# ATmega16M1 device description
Architecture: AVR8; Family: megaAVR
Registers are 8-bit, access not given, no defined reset value unless marked. A register's access mark holds for its fields unless they carry their own. Offsets are from the block's base; [hi:lo] are bit positions; {n}, {i} and the like mark numbered series.

## TC0 (TC8 module) — Timer/Counter, 8-bit
Instances: TC0 0x00
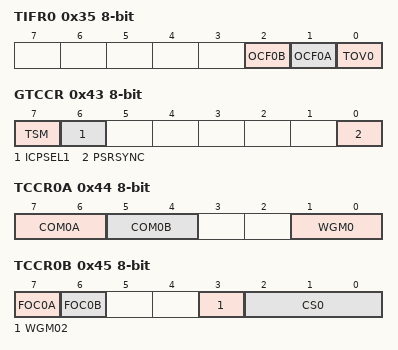
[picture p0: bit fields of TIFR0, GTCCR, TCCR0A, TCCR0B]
0x35 TIFR0 — Timer/Counter0 Interrupt Flag register
  [2] OCF0B — Timer/Counter0 Output Compare Flag 0B
  [1] OCF0A — Timer/Counter0 Output Compare Flag 0A
  [0] TOV0 — Timer/Counter0 Overflow Flag
0x43 GTCCR — General Timer/Counter Control Register
  [7] TSM — Timer/Counter Synchronization Mode
  [6] ICPSEL1 — Timer/Counter1 Input Capture Selection
  [0] PSRSYNC — Timer/Counter Prescaler Reset
0x44 TCCR0A — Timer/Counter Control Register A
  [7:6] COM0A — Compare Output Mode for Channel A
  [5:4] COM0B — Compare Output Mode for Channel B
  [1:0] WGM0 — Waveform Generation Mode
0x45 TCCR0B — Timer/Counter Control Register B
  [7] FOC0A — Force Output Compare A
  [6] FOC0B — Force Output Compare B
  [3] WGM02
  [2:0] CS0 — Clock Select
    0=No Clock Source (Stopped); 1=Running, No Prescaling; 2=Running, CLK/8; 3=Running, CLK/64; 4=Running, CLK/256; 5=Running, CLK/1024; 6=Running, ExtClk Tx Falling Edge; 7=Running, ExtClk Tx Rising Edge
0x46 TCNT0 — Timer/Counter0
  [7:0] TCNT0 — Timer/Counter0 bits
0x47 OCR0A — Timer/Counter0 Output Compare Register A
  [7:0] OCR0A — Timer/Counter0 Output Compare bits
0x48 OCR0B — Timer/Counter0 Output Compare Register B
  [7:0] OCR0B — Timer/Counter0 Output Compare bits
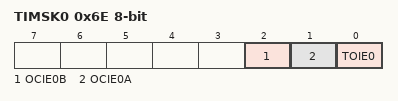
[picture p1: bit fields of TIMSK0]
0x6E TIMSK0 — Timer/Counter0 Interrupt Mask Register
  [2] OCIE0B — Timer/Counter0 Output Compare Match B Interrupt Enable
  [1] OCIE0A — Timer/Counter0 Output Compare Match A Interrupt Enable
  [0] TOIE0 — Timer/Counter0 Overflow Interrupt Enable

## TC1 (TC16 module) — Timer/Counter, 16-bit
Instances: TC1 0x00
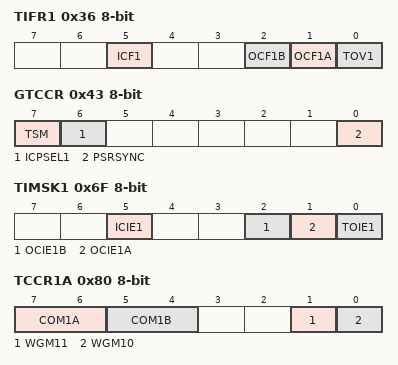
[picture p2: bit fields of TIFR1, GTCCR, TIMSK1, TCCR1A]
0x36 TIFR1 — Timer/Counter Interrupt Flag register
  [5] ICF1 — Input Capture Flag 1
  [2] OCF1B — Output Compare Flag 1B
  [1] OCF1A — Output Compare Flag 1A
  [0] TOV1 — Timer/Counter1 Overflow Flag
0x43 GTCCR — General Timer/Counter Control Register
  [7] TSM — Timer/Counter Synchronization Mode
  [6] ICPSEL1 — Timer/Counter1 Input Capture Selection
  [0] PSRSYNC — Timer/Counter Prescaler Reset
0x6F TIMSK1 — Timer/Counter Interrupt Mask Register
  [5] ICIE1 — Timer/Counter1 Input Capture Interrupt Enable
  [2] OCIE1B — Timer/Counter1 Output CompareB Match Interrupt Enable
  [1] OCIE1A — Timer/Counter1 Output CompareA Match Interrupt Enable
  [0] TOIE1 — Timer/Counter1 Overflow Interrupt Enable
0x80 TCCR1A — Timer/Counter1 Control Register A
  [7:6] COM1A — Compare Output Mode for Channel A
  [5:4] COM1B — Compare Output Mode for Channel B
  [1] WGM11 — Waveform Generation Mode
  [0] WGM10 — Waveform Generation Mode
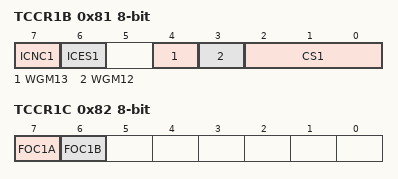
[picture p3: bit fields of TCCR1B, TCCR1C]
0x81 TCCR1B — Timer/Counter1 Control Register B
  [7] ICNC1 — Input Capture 1 Noise Canceler
  [6] ICES1 — Input Capture 1 Edge Select
  [4] WGM13 (bit 2 of the value upward) — Waveform Generation Mode
  [3] WGM12 (bit 2 of the value upward) — Waveform Generation Mode
  [2:0] CS1 — Prescaler source of Timer/Counter 1
    0=No Clock Source (Stopped); 1=Running, No Prescaling; 2=Running, CLK/8; 3=Running, CLK/64; 4=Running, CLK/256; 5=Running, CLK/1024; 6=Running, ExtClk Tx Falling Edge; 7=Running, ExtClk Tx Rising Edge
0x82 TCCR1C — Timer/Counter1 Control Register C
  [7] FOC1A — Force Output Compare for Channel A
  [6] FOC1B — Force Output Compare for Channel B
0x84 TCNT1 16-bit — Timer/Counter1 Bytes
  [15:0] TCNT1 — Timer/Counter1 bits
0x86 ICR1 16-bit — Timer/Counter1 Input Capture Register
  [15:0] ICR1 — Timer/Counter1 Input Capture bits
0x88 OCR1A 16-bit — Timer/Counter1 Output Compare Register A
  [15:0] OCR1A — Timer/Counter1 Output Compare bits
0x8A OCR1B 16-bit — Timer/Counter1 Output Compare Register B
  [15:0] OCR1B — Timer/Counter1 Output Compare bits

## ADC — Analog-to-Digital Converter
Instances: ADC 0x00
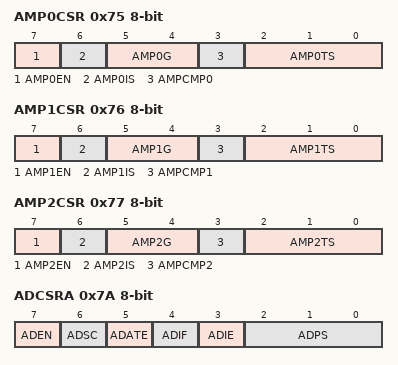
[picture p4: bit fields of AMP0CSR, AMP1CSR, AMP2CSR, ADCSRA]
0x75 AMP0CSR — Amplifier 0 Control and Status Register
  [7] AMP0EN — Amplifier 0 Enable
  [6] AMP0IS — Amplifier 0 Input Shunt
  [5:4] AMP0G — Amplifier 0 Gain Selection
  [3] AMPCMP0 — Amplifier 0 - Comparator 0 connection
  [2:0] AMP0TS — Amplifier 0 Clock Source Selection
0x76 AMP1CSR — Amplifier 1 Control and Status Register
  [7] AMP1EN — Amplifier 1 Enable
  [6] AMP1IS — Amplifier 1 Input Shunt
  [5:4] AMP1G — Amplifier 1 Gain Selection
  [3] AMPCMP1 — Amplifier 1 - Comparator 1 Connection
  [2:0] AMP1TS — Amplifier 1 Clock Source Selection
0x77 AMP2CSR — Amplifier 2 Control and Status Register
  [7] AMP2EN — Amplifier 2 Enable
  [6] AMP2IS — Amplifier 2 Input Shunt
  [5:4] AMP2G — Amplifier 2 Gain Selection
  [3] AMPCMP2 — Amplifier 2 - Comparator 2 Connection
  [2:0] AMP2TS — Amplifier 2 Clock Source Selection
0x78 ADC 16-bit — ADC Data Register Bytes
  [15:0] ADC — ADC Data bits
0x7A ADCSRA — The ADC Control and Status register
  [7] ADEN — ADC Enable
  [6] ADSC — ADC Start Conversion
  [5] ADATE — ADC Auto Trigger Enable
  [4] ADIF — ADC Interrupt Flag
  [3] ADIE — ADC Interrupt Enable
  [2:0] ADPS — ADC Prescaler Select Bits
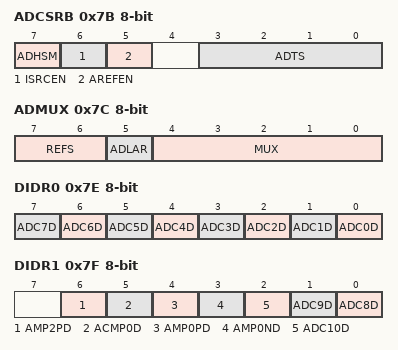
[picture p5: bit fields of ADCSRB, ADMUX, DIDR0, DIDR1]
0x7B ADCSRB — ADC Control and Status Register B
  [7] ADHSM — ADC High Speed Mode
  [6] ISRCEN — Current Source Enable
  [5] AREFEN — Analog Reference pin Enable
  [3:0] ADTS — ADC Auto Trigger Sources
    0=Free Running mode; 1=Analog Comparator; 2=External Interrupt Request 0; 3=Timer/Counter0 Compare Match A; 4=Timer/Counter0 Overflow; 5=Timer/Counter1 Compare Match B; 6=Timer/Counter1 Overflow; 7=Timer/Counter1 Capture Event; 8=PSC0ASY Event; 9=PSC1ASY Event; 10=PSC2ASY Event; 11=Analog comparator 1; 12=Analog comparator 2
0x7C ADMUX — The ADC multiplexer Selection Register
  [7:6] REFS — Reference Selection Bits
    0=AREF, Internal Vref turned off; 1=AVCC with external capacitor at AREF pin; 3=Internal 2.56V Voltage Reference with external capacitor at AREF pin
  [5] ADLAR — Left Adjust Result
  [4:0] MUX — Analog Channel and Gain Selection Bits
    {v}=ADC{v} (ADC input pin {v}) (v=0..10); 11=TEMPSENSE (Temperature sensor); 12=VCC4 (Internal VCC / 4); 13=ISRC (Current source); 14=AMP0 (Analog Differential Amplifier 0); 15=AMP1 (Analog Differential Amplifier 1); 16=AMP2 (Analog Differential Amplifier 2); 17=BNDGAP (Bandgap); 18=GND (0V (GND))
0x7E DIDR0 — Digital Input Disable Register 0
  [n] ADC{n}D (n=0..7) — ADC{n} Digital input Disable
0x7F DIDR1 — Digital Input Disable Register 0
  [6] AMP2PD — AMP2P Pin Digital input Disable
  [5] ACMP0D — ACMP0 Pin Digital input Disable
  [4] AMP0PD — AMP0P Pin Digital input Disable
  [3] AMP0ND — AMP0N Pin Digital input Disable
  [2] ADC10D — ADC10 Pin Digital input Disable
  [1] ADC9D — ADC9 Pin Digital input Disable
  [0] ADC8D — ADC8 Pin Digital input Disable
